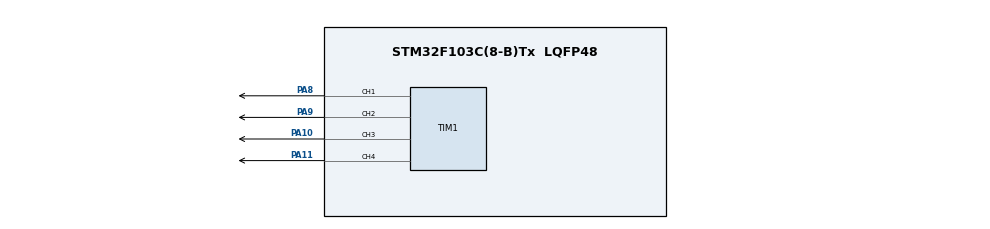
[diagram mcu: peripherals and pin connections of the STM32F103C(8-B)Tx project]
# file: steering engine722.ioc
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Mcu.Family=STM32F1
Mcu.Name=STM32F103C(8-B)Tx
Mcu.Package=LQFP48
NVIC.PriorityGroup=NVIC_PRIORITYGROUP_4
PA10.Signal=S_TIM1_CH3
PA11.Signal=S_TIM1_CH4
PA13.Mode=Serial_Wire
PA13.Signal=SYS_JTMS-SWDIO
PA14.Mode=Serial_Wire
PA14.Signal=SYS_JTCK-SWCLK
PA8.Signal=S_TIM1_CH1
PA9.Signal=S_TIM1_CH2
ProjectManager.HeapSize=0x200
ProjectManager.StackSize=0x400
ProjectManager.TargetToolchain=MDK-ARM V5.27
RCC.APB1Freq_Value=8000000
RCC.APB2Freq_Value=8000000
SH.S_TIM1_CH1.0=TIM1_CH1,PWM Generation1 CH1
SH.S_TIM1_CH2.0=TIM1_CH2,Output Compare2 CH2
SH.S_TIM1_CH3.0=TIM1_CH3,Output Compare3 CH3
SH.S_TIM1_CH4.0=TIM1_CH4,Output Compare4 CH4
TIM1.Channel-Output\ Compare2\ CH2=TIM_CHANNEL_2
TIM1.Channel-Output\ Compare3\ CH3=TIM_CHANNEL_3
TIM1.Channel-Output\ Compare4\ CH4=TIM_CHANNEL_4
TIM1.Channel-PWM\ Generation1\ CH1=TIM_CHANNEL_1
board=custom

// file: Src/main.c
/* USER CODE BEGIN Header */
/**
  ******************************************************************************
  * @file           : main.c
  * @brief          : Main program body
  ******************************************************************************
  * @attention
  *
  * <h2><center>&copy; Copyright (c) 2021 STMicroelectronics.
  * All rights reserved.</center></h2>
  *
  * This software component is licensed by ST under BSD 3-Clause license,
  * the "License"; You may not use this file except in compliance with the
  * License. You may obtain a copy of the License at:
  *                        opensource.org/licenses/BSD-3-Clause
  *
  ******************************************************************************
  */
/* USER CODE END Header */
#include "main.h"

/* USER CODE BEGIN Includes */
#include <stdio.h>
/* USER CODE END Includes */

TIM_HandleTypeDef htim1;

void SystemClock_Config(void);
static void MX_GPIO_Init(void);
static void MX_TIM1_Init(void);

int main(void)
{

  /* MCU Configuration--------------------------------------------------------*/

  /* Reset of all peripherals, Initializes the Flash interface and the Systick. */
  HAL_Init();

  /* Configure the system clock */
  SystemClock_Config();

  /* Initialize all configured peripherals */
  MX_GPIO_Init();
  MX_TIM1_Init();

  /* Infinite loop */
  /* USER CODE BEGIN WHILE */
  while (1)
  {

		HAL_TIMEx_PWMN_Start(&htim1,1);
    /* USER CODE END WHILE */

  }
}

void SystemClock_Config(void)
{
  RCC_OscInitTypeDef RCC_OscInitStruct = {0};
  RCC_ClkInitTypeDef RCC_ClkInitStruct = {0};

  /** Initializes the RCC Oscillators according to the specified parameters
  * in the RCC_OscInitTypeDef structure.
  */
  RCC_OscInitStruct.OscillatorType = RCC_OSCILLATORTYPE_HSI;
  RCC_OscInitStruct.HSIState = RCC_HSI_ON;
  RCC_OscInitStruct.HSICalibrationValue = RCC_HSICALIBRATION_DEFAULT;
  RCC_OscInitStruct.PLL.PLLState = RCC_PLL_NONE;
  if (HAL_RCC_OscConfig(&RCC_OscInitStruct) != HAL_OK)
  {
    Error_Handler();
  }
  /** Initializes the CPU, AHB and APB buses clocks
  */
  RCC_ClkInitStruct.ClockType = RCC_CLOCKTYPE_HCLK|RCC_CLOCKTYPE_SYSCLK
                              |RCC_CLOCKTYPE_PCLK1|RCC_CLOCKTYPE_PCLK2;
  RCC_ClkInitStruct.SYSCLKSource = RCC_SYSCLKSOURCE_HSI;
  RCC_ClkInitStruct.AHBCLKDivider = RCC_SYSCLK_DIV1;
  RCC_ClkInitStruct.APB1CLKDivider = RCC_HCLK_DIV1;
  RCC_ClkInitStruct.APB2CLKDivider = RCC_HCLK_DIV1;

  if (HAL_RCC_ClockConfig(&RCC_ClkInitStruct, FLASH_LATENCY_0) != HAL_OK)
  {
    Error_Handler();
  }
}

static void MX_TIM1_Init(void)
{

  TIM_MasterConfigTypeDef sMasterConfig = {0};
  TIM_OC_InitTypeDef sConfigOC = {0};
  TIM_BreakDeadTimeConfigTypeDef sBreakDeadTimeConfig = {0};

  htim1.Instance = TIM1;
  htim1.Init.Prescaler = 0;
  htim1.Init.CounterMode = TIM_COUNTERMODE_UP;
  htim1.Init.Period = 65535;
  htim1.Init.ClockDivision = TIM_CLOCKDIVISION_DIV1;
  htim1.Init.RepetitionCounter = 0;
  htim1.Init.AutoReloadPreload = TIM_AUTORELOAD_PRELOAD_DISABLE;
  if (HAL_TIM_PWM_Init(&htim1) != HAL_OK)
  {
    Error_Handler();
  }
  if (HAL_TIM_OC_Init(&htim1) != HAL_OK)
  {
    Error_Handler();
  }
  sMasterConfig.MasterOutputTrigger = TIM_TRGO_RESET;
  sMasterConfig.MasterSlaveMode = TIM_MASTERSLAVEMODE_DISABLE;
  if (HAL_TIMEx_MasterConfigSynchronization(&htim1, &sMasterConfig) != HAL_OK)
  {
    Error_Handler();
  }
  sConfigOC.OCMode = TIM_OCMODE_PWM1;
  sConfigOC.Pulse = 0;
  sConfigOC.OCPolarity = TIM_OCPOLARITY_HIGH;
  sConfigOC.OCNPolarity = TIM_OCNPOLARITY_HIGH;
  sConfigOC.OCFastMode = TIM_OCFAST_DISABLE;
  sConfigOC.OCIdleState = TIM_OCIDLESTATE_RESET;
  sConfigOC.OCNIdleState = TIM_OCNIDLESTATE_RESET;
  if (HAL_TIM_PWM_ConfigChannel(&htim1, &sConfigOC, TIM_CHANNEL_1) != HAL_OK)
  {
    Error_Handler();
  }
  sConfigOC.OCMode = TIM_OCMODE_TIMING;
  if (HAL_TIM_OC_ConfigChannel(&htim1, &sConfigOC, TIM_CHANNEL_2) != HAL_OK)
  {
    Error_Handler();
  }
  if (HAL_TIM_OC_ConfigChannel(&htim1, &sConfigOC, TIM_CHANNEL_3) != HAL_OK)
  {
    Error_Handler();
  }
  if (HAL_TIM_OC_ConfigChannel(&htim1, &sConfigOC, TIM_CHANNEL_4) != HAL_OK)
  {
    Error_Handler();
  }
  sBreakDeadTimeConfig.OffStateRunMode = TIM_OSSR_DISABLE;
  sBreakDeadTimeConfig.OffStateIDLEMode = TIM_OSSI_DISABLE;
  sBreakDeadTimeConfig.LockLevel = TIM_LOCKLEVEL_OFF;
  sBreakDeadTimeConfig.DeadTime = 0;
  sBreakDeadTimeConfig.BreakState = TIM_BREAK_DISABLE;
  sBreakDeadTimeConfig.BreakPolarity = TIM_BREAKPOLARITY_HIGH;
  sBreakDeadTimeConfig.AutomaticOutput = TIM_AUTOMATICOUTPUT_DISABLE;
  if (HAL_TIMEx_ConfigBreakDeadTime(&htim1, &sBreakDeadTimeConfig) != HAL_OK)
  {
    Error_Handler();
  }
  HAL_TIM_MspPostInit(&htim1);

}

static void MX_GPIO_Init(void)
{

  /* GPIO Ports Clock Enable */
  __HAL_RCC_GPIOA_CLK_ENABLE();

}

void Error_Handler(void)
{
}

/************************ (C) COPYRIGHT STMicroelectronics *****END OF FILE****/
